# f28004x_mem_cfg_regs register map
Vendor: Texas Instruments
Peripheral module from a debugger description file (folder C2000).
Address unit: 16 bits
Registers are 32-bit, read-write, no defined reset value unless marked. A register's access mark holds for its fields unless they carry their own. Offsets are as the file gives them; lines under a group give offsets from that group; [hi:lo] are bit positions; {n}, {i} and the like mark numbered series; 'fields as' and 'values as' point back to an identical list; <NAME> marks a mode.

## MEM_CFG_REGS — MEM CFG Registers
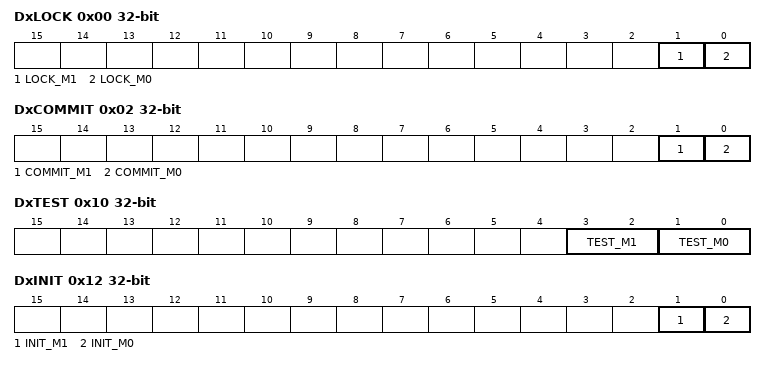
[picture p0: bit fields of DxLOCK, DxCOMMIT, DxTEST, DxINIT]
0x00 DxLOCK — Dedicated RAM Config Lock Register
  [1] LOCK_M1 — M1 RAM Lock bits
  [0] LOCK_M0 — M0 RAM Lock bits
0x02 DxCOMMIT access not given — Dedicated RAM Config Lock Commit Register
  [1] COMMIT_M1 — M1 RAM Permanent Lock bits (access R/SOnce)
  [0] COMMIT_M0 — M0 RAM Permanent Lock bits (access R/SOnce)
0x08 DxACCPROT0 access not given — Dedicated RAM Config Register
0x10 DxTEST — Dedicated RAM TEST Register
  [3:2] TEST_M1 — Selects the different modes for M1 RAM
  [1:0] TEST_M0 — Selects the different modes for M0 RAM
0x12 DxINIT access not given — Dedicated RAM Init Register
  [1] INIT_M1 — RAM Initialization control for M1 RAM. (access R=0/W=1)
  [0] INIT_M0 — RAM Initialization control for M0 RAM. (access R=0/W=1)
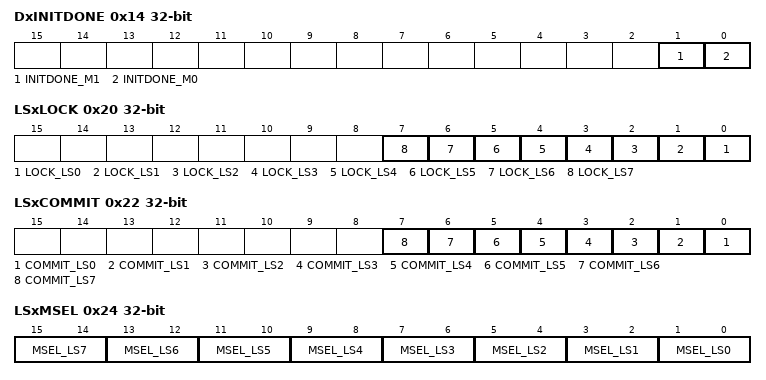
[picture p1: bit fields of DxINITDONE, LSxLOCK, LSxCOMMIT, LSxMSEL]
0x14 DxINITDONE ro — Dedicated RAM InitDone Status Register
  [1] INITDONE_M1 — RAM Initialization status for M1 RAM.
  [0] INITDONE_M0 — RAM Initialization status for M0 RAM.
0x20 LSxLOCK — Local Shared RAM Config Lock Register
  [n] LOCK_LS{n} (n=0..7) — LS{n} RAM Lock bits
0x22 LSxCOMMIT access not given — Local Shared RAM Config Lock Commit Register
  [n] COMMIT_LS{n} (n=0..7) — LS{n} RAM Permanent Lock bits (access R/SOnce)
0x24 LSxMSEL — Local Shared RAM Master Sel Register
  [2n+1:2n] MSEL_LS{n} (n=0..7) — Master Select for LS{n} RAM
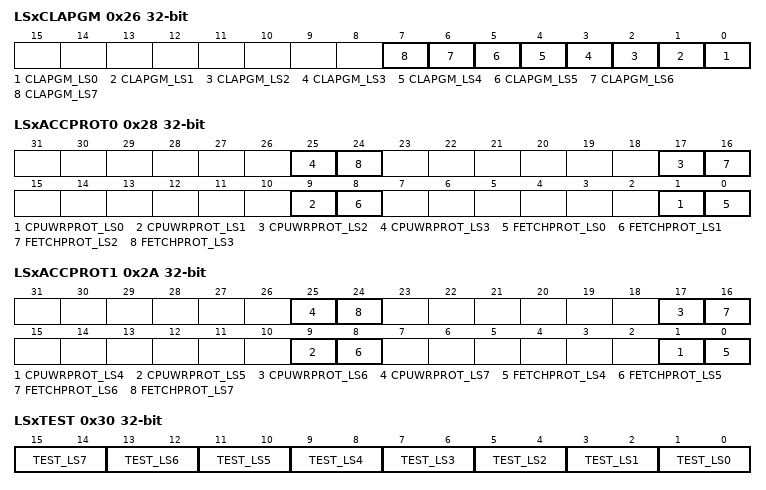
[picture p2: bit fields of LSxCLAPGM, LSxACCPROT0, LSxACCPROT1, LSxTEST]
0x26 LSxCLAPGM — Local Shared RAM Prog/Exe control Register
  [n] CLAPGM_LS{n} (n=0..7) — Selects LS{n} RAM as program vs data memory for CLA
0x28 LSxACCPROT0 — Local Shared RAM Config Register 0
  [8n+1] CPUWRPROT_LS{n} (n=0..3) — CPU WR Protection For LS{n} RAM
  [8n] FETCHPROT_LS{n} (n=0..3) — Fetch Protection For LS{n} RAM
0x2A LSxACCPROT1 — Local Shared RAM Config Register 1
  [8n-31] CPUWRPROT_LS{n} (n=4..7) — CPU WR Protection For LS{n} RAM
  [8n-32] FETCHPROT_LS{n} (n=4..7) — Fetch Protection For LS{n} RAM
0x30 LSxTEST — Local Shared RAM TEST Register
  [2n+1:2n] TEST_LS{n} (n=0..7) — Selects the different modes for LS{n} RAM
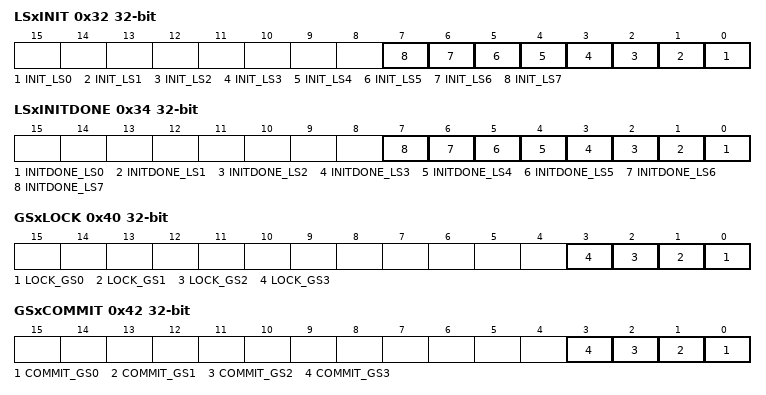
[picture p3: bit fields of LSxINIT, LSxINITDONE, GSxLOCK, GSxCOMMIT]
0x32 LSxINIT access not given — Local Shared RAM Init Register
  [n] INIT_LS{n} (n=0..7) — RAM Initialization control for LS{n} RAM. (access R=0/W=1)
0x34 LSxINITDONE ro — Local Shared RAM InitDone Status Register
  [n] INITDONE_LS{n} (n=0..7) — RAM Initialization status for LS{n} RAM.
0x40 GSxLOCK — Global Shared RAM Config Lock Register
  [n] LOCK_GS{n} (n=0..3) — GS{n} RAM Lock bits
0x42 GSxCOMMIT access not given — Global Shared RAM Config Lock Commit Register
  [n] COMMIT_GS{n} (n=0..3) — GS{n} RAM Permanent Lock bits (access R/SOnce)
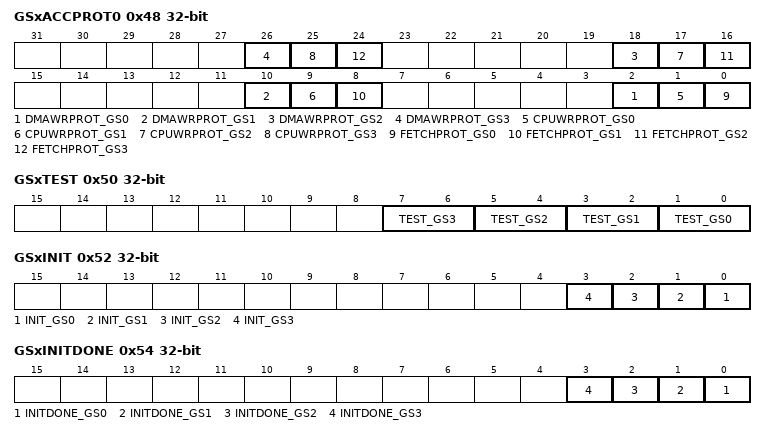
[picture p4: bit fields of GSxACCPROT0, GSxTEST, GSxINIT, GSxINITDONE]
0x48 GSxACCPROT0 — Global Shared RAM Config Register 0
  [8n+2] DMAWRPROT_GS{n} (n=0..3) — DMA WR Protection For GS{n} RAM
  [8n+1] CPUWRPROT_GS{n} (n=0..3) — CPU WR Protection For GS{n} RAM
  [8n] FETCHPROT_GS{n} (n=0..3) — Fetch Protection For GS{n} RAM
{0x48+2i} GSxACCPROT{i} access not given (i=1..3) — Global Shared RAM Config Register {i}
0x50 GSxTEST — Global Shared RAM TEST Register
  [2n+1:2n] TEST_GS{n} (n=0..3) — Selects the different modes for GS{n} RAM
0x52 GSxINIT access not given — Global Shared RAM Init Register
  [n] INIT_GS{n} (n=0..3) — RAM Initialization control for GS{n} RAM. (access R=0/W=1)
0x54 GSxINITDONE ro — Global Shared RAM InitDone Status Register
  [n] INITDONE_GS{n} (n=0..3) — RAM Initialization status for GS{n} RAM.
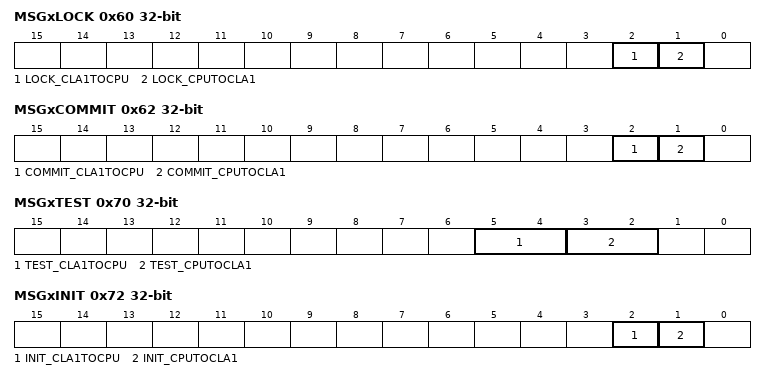
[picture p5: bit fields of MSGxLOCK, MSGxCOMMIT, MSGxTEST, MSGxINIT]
0x60 MSGxLOCK — Message RAM Config Lock Register
  [2] LOCK_CLA1TOCPU — CLA1TOCPU RAM Lock bits
  [1] LOCK_CPUTOCLA1 — CPUTOCLA1 RAM Lock bits
0x62 MSGxCOMMIT access not given — Message RAM Config Lock Commit Register
  [2] COMMIT_CLA1TOCPU — CLA1TOCPU RAM control fields COMMIT bit (access R/SOnce)
  [1] COMMIT_CPUTOCLA1 — CPUTOCLA1 RAM control fields COMMIT bit (access R/SOnce)
0x70 MSGxTEST — Message RAM TEST Register
  [5:4] TEST_CLA1TOCPU — CLA1 to CPU MSG RAM Mode Select
  [3:2] TEST_CPUTOCLA1 — CPU to CLA1 MSG RAM Mode Select
0x72 MSGxINIT access not given — Message RAM Init Register
  [2] INIT_CLA1TOCPU — Initialization control for CLA1TOCPU MSG RAM (access R=0/W=1)
  [1] INIT_CPUTOCLA1 — Initialization control for CPUTOCLA1 MSG RAM (access R=0/W=1)
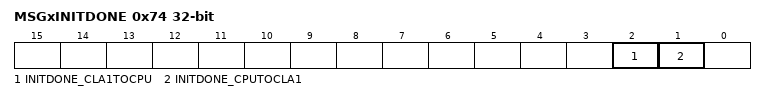
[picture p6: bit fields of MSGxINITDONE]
0x74 MSGxINITDONE ro — Message RAM InitDone Status Register
  [2] INITDONE_CLA1TOCPU — Initialization status for CLA1 to CPU MSG RAM
  [1] INITDONE_CPUTOCLA1 — Initialization status for CPU to CLA1 MSG RAM
